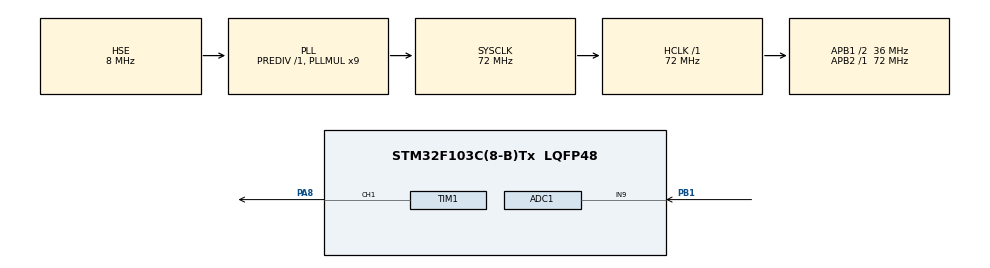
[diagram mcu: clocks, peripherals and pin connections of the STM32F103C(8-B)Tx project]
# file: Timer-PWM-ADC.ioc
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ADC1.Channel-5\#ChannelRegularConversion=ADC_CHANNEL_9
ADC1.ContinuousConvMode=ENABLE
ADC1.NbrOfConversionFlag=1
ADC1.Rank-5\#ChannelRegularConversion=1
ADC1.SamplingTime-5\#ChannelRegularConversion=ADC_SAMPLETIME_1CYCLE_5
ADC1.master=1
Mcu.Family=STM32F1
Mcu.Name=STM32F103C(8-B)Tx
Mcu.Package=LQFP48
NVIC.PriorityGroup=NVIC_PRIORITYGROUP_4
PA8.Signal=S_TIM1_CH1
PB1.Signal=ADCx_IN9
PD0-OSC_IN.Mode=HSE-External-Oscillator
PD0-OSC_IN.Signal=RCC_OSC_IN
PD1-OSC_OUT.Mode=HSE-External-Oscillator
PD1-OSC_OUT.Signal=RCC_OSC_OUT
ProjectManager.HeapSize=0x200
ProjectManager.StackSize=0x400
ProjectManager.TargetToolchain=STM32CubeIDE
RCC.ADCPresc=RCC_ADCPCLK2_DIV6
RCC.AHBFreq_Value=72000000
RCC.APB1CLKDivider=RCC_HCLK_DIV2
RCC.APB1Freq_Value=36000000
RCC.APB1TimFreq_Value=72000000
RCC.APB2Freq_Value=72000000
RCC.APB2TimFreq_Value=72000000
RCC.HCLKFreq_Value=72000000
RCC.PLLMUL=RCC_PLL_MUL9
RCC.PLLSourceVirtual=RCC_PLLSOURCE_HSE
RCC.SYSCLKFreq_VALUE=72000000
RCC.SYSCLKSource=RCC_SYSCLKSOURCE_PLLCLK
RCC.USBFreq_Value=72000000
SH.ADCx_IN9.0=ADC1_IN9,IN9
SH.S_TIM1_CH1.0=TIM1_CH1,PWM Generation1 CH1
TIM1.Channel-PWM\ Generation1\ CH1=TIM_CHANNEL_1
TIM1.Period=19999
TIM1.Prescaler=71
TIM1.Pulse-PWM\ Generation1\ CH1=1000
VP_SYS_VS_ND.Mode=No_Debug
VP_TIM1_VS_ClockSourceINT.Mode=Internal
board=custom

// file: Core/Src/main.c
/* USER CODE BEGIN Header */
/**
 ******************************************************************************
 * @file           : main.c
 * @brief          : Main program body
 ******************************************************************************
 * @attention
 *
 * Copyright (c) 2024 STMicroelectronics.
 * All rights reserved.
 *
 * This software is licensed under terms that can be found in the LICENSE file
 * in the root directory of this software component.
 * If no LICENSE file comes with the software, it is provided AS-IS.
 *
 ******************************************************************************
 */
/* USER CODE END Header */
#include "main.h"

/* USER CODE BEGIN Includes */

// Include standard integer definitions
#include <stdint.h>
// Include header for HD44780 LCD driver
#include "../../Drivers/Device_Drivers/HD44780_LCD/HD44780_LCD.h"

/* USER CODE END Includes */

/* USER CODE BEGIN PD */
// Define the maximum PWM value
#define MAX_PWM 2000
// Define the minimum PWM value
#define MIN_PWM 998
// Define the maximum angle value
#define MAX_ANGLE 90
// Define the minimum angle value
#define MIN_ANGLE -90
// Define the maximum ADC raw value
#define MAX_ADC_RAW 4020
// Define the minimum ADC raw value
#define MIN_ADC_RAW 0
/* USER CODE END PD */

ADC_HandleTypeDef hadc1;

TIM_HandleTypeDef htim1;

void SystemClock_Config(void);
static void MX_GPIO_Init(void);
static void MX_TIM1_Init(void);
static void MX_ADC1_Init(void);

/* USER CODE BEGIN 0 */
// Initialize the LCD struct with GPIO pins
Alcd_t lcd =
    { .RS_GPIO = GPIOA, .RS_GPIO_Pin = GPIO_PIN_4, .EN_GPIO = GPIOA,
        .EN_GPIO_Pin = GPIO_PIN_5, .Data_GPIO = GPIOA,
        .Data_GPIO_Start_Pin = 0 };
/* USER CODE END 0 */

int main(void) {

    /* MCU Configuration--------------------------------------------------------*/

    /* Reset of all peripherals, Initializes the Flash interface and the Systick. */
    HAL_Init();

    /* Configure the system clock */
    SystemClock_Config();

    /* Initialize all configured peripherals */
    MX_GPIO_Init();
    MX_TIM1_Init();
    MX_ADC1_Init();
    /* USER CODE BEGIN 2 */

    // Start the base timer for Timer 1
    HAL_TIM_Base_Start(&htim1);

    // Start the PWM generation for Timer 1 Channel 1
    HAL_TIM_PWM_Start(&htim1, TIM_CHANNEL_1);

    // Initialize the LCD with 2 lines and 16 columns
    Alcd_Init(&lcd, 2, 16);

    // Set initial PWM duty cycle to center value (neutral position = 0 angle)
    TIM1->CCR1 = 1499;

    // Declare variables for display and calculation
    char str[16];
    int16_t message;
    float angle = 0;
    float pwm_cycle;
    int16_t adc_voltage;

    // Clear the LCD
    Alcd_Clear(&lcd);
    // Display initial messages on the LCD
    Alcd_PutAt(&lcd, 0, 0, "The angle range");
    Alcd_PutAt(&lcd, 1, 0, "is 90 and -90");
    HAL_Delay(2000);
    Alcd_Clear(&lcd);

    // Start ADC
    HAL_ADC_Start(&hadc1);

    // Wait for ADC conversion to complete
    HAL_ADC_PollForConversion(&hadc1, 100);

    /* USER CODE END 2 */

    /* Infinite loop */
    while (1) {

        /* USER CODE BEGIN 3 */

        // Clear the LCD
        Alcd_Clear(&lcd);

        // Get ADC value
        adc_voltage = HAL_ADC_GetValue(&hadc1);

        // Display ADC value on the LCD
        message = sprintf(str, "signal = %d", adc_voltage);
        Alcd_PutAt_n(&lcd, 0, 0, str, message);

        // Convert the input ADC value to an angle
        angle = ((float) adc_voltage * 0.044776) - 90;

        // Limit the angle to the maximum allowed value
        if (angle > MAX_ANGLE) {
            angle = MAX_ANGLE;
        }

        // Limit the angle to the minimum allowed value
        if (angle < MIN_ANGLE) {
            angle = MIN_ANGLE;
        }

        // Display the current angle on the LCD
        message = sprintf(str, "angle = %.2f", angle);
        Alcd_PutAt_n(&lcd, 1, 0, str, message);

        // Calculate the PWM duty cycle based on the angle
        pwm_cycle = (5.5555 * angle) + 1499;

        // Ensure the PWM duty cycle is within the allowed range
        if ((MIN_PWM < pwm_cycle) & (pwm_cycle < MAX_PWM)) {
            // Update the PWM duty cycle
            TIM1->CCR1 = pwm_cycle;
        }

        // Delay for a short period
        HAL_Delay(500);
    }
    /* USER CODE END 3 */
}

void SystemClock_Config(void) {
    RCC_OscInitTypeDef RCC_OscInitStruct = { 0 };
    RCC_ClkInitTypeDef RCC_ClkInitStruct = { 0 };
    RCC_PeriphCLKInitTypeDef PeriphClkInit = { 0 };

    /** Initializes the RCC Oscillators according to the specified parameters
     * in the RCC_OscInitTypeDef structure.
     */
    RCC_OscInitStruct.OscillatorType = RCC_OSCILLATORTYPE_HSE;
    RCC_OscInitStruct.HSEState = RCC_HSE_ON;
    RCC_OscInitStruct.HSEPredivValue = RCC_HSE_PREDIV_DIV1;
    RCC_OscInitStruct.HSIState = RCC_HSI_ON;
    RCC_OscInitStruct.PLL.PLLState = RCC_PLL_ON;
    RCC_OscInitStruct.PLL.PLLSource = RCC_PLLSOURCE_HSE;
    RCC_OscInitStruct.PLL.PLLMUL = RCC_PLL_MUL9;
    if (HAL_RCC_OscConfig(&RCC_OscInitStruct) != HAL_OK) {
        Error_Handler();
    }

    /** Initializes the CPU, AHB and APB buses clocks
     */
    RCC_ClkInitStruct.ClockType = RCC_CLOCKTYPE_HCLK | RCC_CLOCKTYPE_SYSCLK
            | RCC_CLOCKTYPE_PCLK1 | RCC_CLOCKTYPE_PCLK2;
    RCC_ClkInitStruct.SYSCLKSource = RCC_SYSCLKSOURCE_PLLCLK;
    RCC_ClkInitStruct.AHBCLKDivider = RCC_SYSCLK_DIV1;
    RCC_ClkInitStruct.APB1CLKDivider = RCC_HCLK_DIV2;
    RCC_ClkInitStruct.APB2CLKDivider = RCC_HCLK_DIV1;

    if (HAL_RCC_ClockConfig(&RCC_ClkInitStruct, FLASH_LATENCY_2) != HAL_OK) {
        Error_Handler();
    }
    PeriphClkInit.PeriphClockSelection = RCC_PERIPHCLK_ADC;
    PeriphClkInit.AdcClockSelection = RCC_ADCPCLK2_DIV6;
    if (HAL_RCCEx_PeriphCLKConfig(&PeriphClkInit) != HAL_OK) {
        Error_Handler();
    }
}

static void MX_ADC1_Init(void) {

    ADC_ChannelConfTypeDef sConfig = { 0 };

    /** Common config
     */
    hadc1.Instance = ADC1;
    hadc1.Init.ScanConvMode = ADC_SCAN_DISABLE;
    hadc1.Init.ContinuousConvMode = ENABLE;
    hadc1.Init.DiscontinuousConvMode = DISABLE;
    hadc1.Init.ExternalTrigConv = ADC_SOFTWARE_START;
    hadc1.Init.DataAlign = ADC_DATAALIGN_RIGHT;
    hadc1.Init.NbrOfConversion = 1;
    if (HAL_ADC_Init(&hadc1) != HAL_OK) {
        Error_Handler();
    }

    /** Configure Regular Channel
     */
    sConfig.Channel = ADC_CHANNEL_9;
    sConfig.Rank = ADC_REGULAR_RANK_1;
    sConfig.SamplingTime = ADC_SAMPLETIME_1CYCLE_5;
    if (HAL_ADC_ConfigChannel(&hadc1, &sConfig) != HAL_OK) {
        Error_Handler();
    }

}

static void MX_TIM1_Init(void) {

    TIM_ClockConfigTypeDef sClockSourceConfig = { 0 };
    TIM_MasterConfigTypeDef sMasterConfig = { 0 };
    TIM_OC_InitTypeDef sConfigOC = { 0 };
    TIM_BreakDeadTimeConfigTypeDef sBreakDeadTimeConfig = { 0 };

    htim1.Instance = TIM1;
    htim1.Init.Prescaler = 71;
    htim1.Init.CounterMode = TIM_COUNTERMODE_UP;
    htim1.Init.Period = 19999;
    htim1.Init.ClockDivision = TIM_CLOCKDIVISION_DIV1;
    htim1.Init.RepetitionCounter = 0;
    htim1.Init.AutoReloadPreload = TIM_AUTORELOAD_PRELOAD_DISABLE;
    if (HAL_TIM_Base_Init(&htim1) != HAL_OK) {
        Error_Handler();
    }
    sClockSourceConfig.ClockSource = TIM_CLOCKSOURCE_INTERNAL;
    if (HAL_TIM_ConfigClockSource(&htim1, &sClockSourceConfig) != HAL_OK) {
        Error_Handler();
    }
    if (HAL_TIM_PWM_Init(&htim1) != HAL_OK) {
        Error_Handler();
    }
    sMasterConfig.MasterOutputTrigger = TIM_TRGO_RESET;
    sMasterConfig.MasterSlaveMode = TIM_MASTERSLAVEMODE_DISABLE;
    if (HAL_TIMEx_MasterConfigSynchronization(&htim1, &sMasterConfig)
            != HAL_OK) {
        Error_Handler();
    }
    sConfigOC.OCMode = TIM_OCMODE_PWM1;
    sConfigOC.Pulse = 1000;
    sConfigOC.OCPolarity = TIM_OCPOLARITY_HIGH;
    sConfigOC.OCNPolarity = TIM_OCNPOLARITY_HIGH;
    sConfigOC.OCFastMode = TIM_OCFAST_DISABLE;
    sConfigOC.OCIdleState = TIM_OCIDLESTATE_RESET;
    sConfigOC.OCNIdleState = TIM_OCNIDLESTATE_RESET;
    if (HAL_TIM_PWM_ConfigChannel(&htim1, &sConfigOC, TIM_CHANNEL_1)
            != HAL_OK) {
        Error_Handler();
    }
    sBreakDeadTimeConfig.OffStateRunMode = TIM_OSSR_DISABLE;
    sBreakDeadTimeConfig.OffStateIDLEMode = TIM_OSSI_DISABLE;
    sBreakDeadTimeConfig.LockLevel = TIM_LOCKLEVEL_OFF;
    sBreakDeadTimeConfig.DeadTime = 0;
    sBreakDeadTimeConfig.BreakState = TIM_BREAK_DISABLE;
    sBreakDeadTimeConfig.BreakPolarity = TIM_BREAKPOLARITY_HIGH;
    sBreakDeadTimeConfig.AutomaticOutput = TIM_AUTOMATICOUTPUT_DISABLE;
    if (HAL_TIMEx_ConfigBreakDeadTime(&htim1, &sBreakDeadTimeConfig)
            != HAL_OK) {
        Error_Handler();
    }
    HAL_TIM_MspPostInit(&htim1);

}

static void MX_GPIO_Init(void) {

    /* GPIO Ports Clock Enable */
    __HAL_RCC_GPIOD_CLK_ENABLE();
    __HAL_RCC_GPIOB_CLK_ENABLE();
    __HAL_RCC_GPIOA_CLK_ENABLE();

}

void Error_Handler(void) {
    /* USER CODE BEGIN Error_Handler_Debug */
    /* User can add his own implementation to report the HAL error return state */
    __disable_irq(); // Disable interrupts
    while (1) {
        // Infinite loop to indicate error
    }
    /* USER CODE END Error_Handler_Debug */
}

#ifdef  USE_FULL_ASSERT
/**
  * @brief  Reports the name of the source file and the source line number
  *         where the assert_param error has occurred.
  * @param  file: pointer to the source file name
  * @param  line: assert_param error line source number
  * @retval None
  */
void assert_failed(uint8_t *file, uint32_t line)
{
  /* USER CODE BEGIN 6 */
  /* User can add their own implementation to report the file name and line number,
     ex: printf("Wrong parameters value: file %s on line %d\r\n", file, line) */
  /* USER CODE END 6 */
}
#endif /* USE_FULL_ASSERT */
